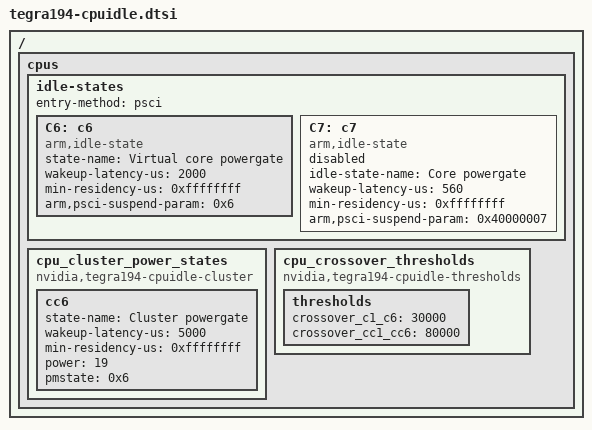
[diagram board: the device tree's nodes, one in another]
/*
 * Copyright (c) 2017-2020, NVIDIA CORPORATION.  All rights reserved.
 *
 * This program is free software; you can redistribute it and/or modify it
 * under the terms and conditions of the GNU General Public License,
 * version 2, as published by the Free Software Foundation.
 *
 * This program is distributed in the hope it will be useful, but WITHOUT
 * ANY WARRANTY; without even the implied warranty of MERCHANTABILITY or
 * FITNESS FOR A PARTICULAR PURPOSE.  See the GNU General Public License for
 * more details.
 *
 * You should have received a copy of the GNU General Public License
 * along with this program.  If not, see <http://www.gnu.org/licenses/>.
 */

/ {
	cpus {
		idle-states {
			entry-method = "psci";

			C6: c6 {
				compatible = "arm,idle-state";
				state-name = "Virtual core powergate";
				wakeup-latency-us = <2000>;
				min-residency-us = <0xffffffff>;
				arm,psci-suspend-param= <0x6>;
				status = "okay";
			};

			C7: c7 {
				compatible = "arm,idle-state";
				idle-state-name = "Core powergate";
				wakeup-latency-us = <560>;
				min-residency-us = <0xffffffff>;
				arm,psci-suspend-param= <0x40000007>;
				status = "disabled";
			};
		};

		cpu_cluster_power_states {
			compatible = "nvidia,tegra194-cpuidle-cluster";
			cc6 {
				state-name = "Cluster powergate";
				wakeup-latency-us = <5000>;
				min-residency-us = <0xffffffff>;
				power = <19>;
				pmstate = <0x6>;
				status = "okay";
			};
		};

		cpu_crossover_thresholds {
			compatible = "nvidia,tegra194-cpuidle-thresholds";

			thresholds {
				crossover_c1_c6         = <30000>;
				crossover_cc1_cc6       = <80000>;
			};
		};
	};
};
